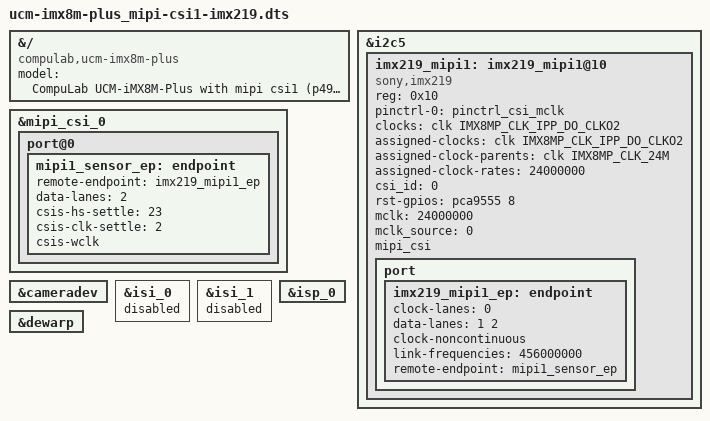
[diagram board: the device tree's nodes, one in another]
/dts-v1/;
/plugin/;

#include "overlay.h"

&{/} {
	model = "CompuLab UCM-iMX8M-Plus with mipi csi1 (p49) enabled";
	compatible = "compulab,ucm-imx8m-plus", "fsl,imx8mp";
};

&i2c5 {
	#address-cells = <1>;
	#size-cells = <0>;
	imx219_mipi1: imx219_mipi1@10 {
		compatible = "sony,imx219";
		reg = <0x10>;
		pinctrl-names = "default";
		pinctrl-0 = <&pinctrl_csi_mclk>;
		clocks = <&clk IMX8MP_CLK_IPP_DO_CLKO2>;
		clock-names = "xclk";
		assigned-clocks = <&clk IMX8MP_CLK_IPP_DO_CLKO2>;
		assigned-clock-parents = <&clk IMX8MP_CLK_24M>;
		assigned-clock-rates = <24000000>;
		csi_id = <0>;
		rst-gpios = <&pca9555 8 GPIO_ACTIVE_HIGH>;
		mclk = <24000000>;
		mclk_source = <0>;

		mipi_csi;
		status = "disabled";

		port {
			imx219_mipi1_ep: endpoint {
				clock-lanes = <0>;
				data-lanes = <1 2>;
				clock-noncontinuous;
				link-frequencies = /bits/ 64 <456000000>;
				remote-endpoint = <&mipi1_sensor_ep>;
			};
		};
	};
};

&imx219_mipi1 {
	status = "okay";
};

&mipi_csi_0 {
	status = "okay";
	port@0 {
		mipi1_sensor_ep: endpoint {
			remote-endpoint = <&imx219_mipi1_ep>;
			data-lanes = <2>;
			csis-hs-settle = <23>;
			csis-clk-settle = <2>;
			csis-wclk;
		};
	};
};

&cameradev {
	status = "okay";
};

&isi_0 {
	status = "disabled";

};

&isi_1 {
	status = "disabled";

};

&isp_0 {
	status = "okay";
};

&dewarp {
	status = "okay";
};
